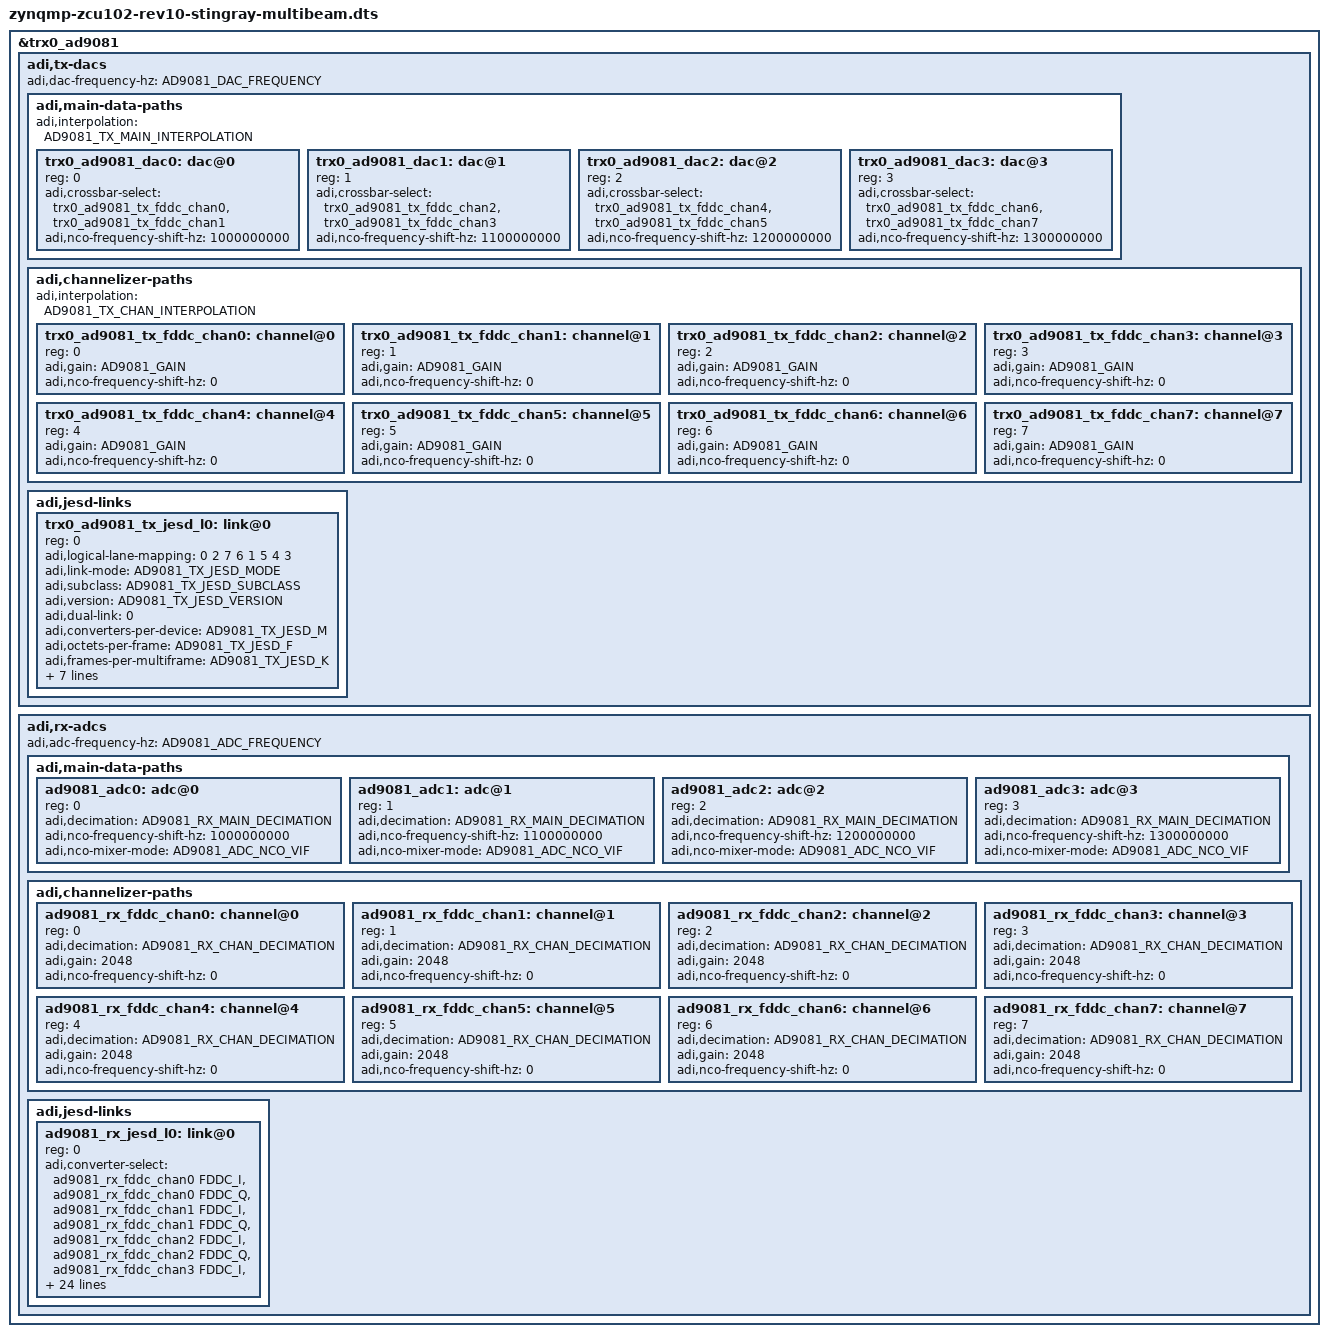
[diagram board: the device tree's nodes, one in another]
// SPDX-License-Identifier: GPL-2.0
/*
 * Analog Devices Stingray
 * https://wiki.analog.com/resources/eval/user-guides/quadmxfe/quick-start
 * https://wiki.analog.com/resources/tools-software/linux-drivers/iio-mxfe/ad9081
 *
 * hdl_project: <ad9081_fmca_ebz_x_band/zcu102>
 * board_revision: <>
 *
 * Copyright (C) 2019-2020 Analog Devices Inc.
 */

#include "zynqmp-zcu102-rev10-stingray.dts"

/*
 *	Lane Rate = 10 Gpbs
 *	Link Clock = 250 MHz
 */

#define AD9081_GAIN			2048

 /* TX path */
#define AD9081_DAC_FREQUENCY			12000000000
#define AD9081_TX_MAIN_INTERPOLATION		8
#define AD9081_TX_CHAN_INTERPOLATION		6

#define AD9081_TX_JESD_MODE			16
#define AD9081_TX_JESD_SUBCLASS			1
#define AD9081_TX_JESD_VERSION			1
#define AD9081_TX_JESD_L			8
#define AD9081_TX_JESD_M			16
#define AD9081_TX_JESD_F			4
#define AD9081_TX_JESD_S			1
#define AD9081_TX_JESD_K			32
#define AD9081_TX_JESD_N			16
#define AD9081_TX_JESD_NP			16
#define AD9081_TX_JESD_CS			0
#define AD9081_TX_JESD_HD			1


 /* RX path */
#define AD9081_ADC_FREQUENCY			6000000000
#define AD9081_RX_MAIN_DECIMATION		6
#define AD9081_RX_CHAN_DECIMATION		4

#define AD9081_RX_JESD_MODE			17
#define AD9081_RX_JESD_SUBCLASS			1
#define AD9081_RX_JESD_VERSION			1
#define AD9081_RX_JESD_L			8
#define AD9081_RX_JESD_M			16
#define AD9081_RX_JESD_F			4
#define AD9081_RX_JESD_S			1
#define AD9081_RX_JESD_K			32
#define AD9081_RX_JESD_N			16
#define AD9081_RX_JESD_NP			16
#define AD9081_RX_JESD_CS			0
#define AD9081_RX_JESD_HD			0


//#define AD9081_JRX_TPL_PHASE_ADJUST		15


&trx0_ad9081 {
	adi,tx-dacs {
		#size-cells = <0>;
		#address-cells = <1>;
		adi,dac-frequency-hz = /bits/ 64 <AD9081_DAC_FREQUENCY>;
		adi,main-data-paths {
			#address-cells = <1>;
			#size-cells = <0>;
			adi,interpolation = <AD9081_TX_MAIN_INTERPOLATION>;
			trx0_ad9081_dac0: dac@0 {
				reg = <0>;
				adi,crossbar-select = <&trx0_ad9081_tx_fddc_chan0>, <&trx0_ad9081_tx_fddc_chan1>;
				adi,nco-frequency-shift-hz = /bits/ 64 <1000000000>; /* 1100 MHz */
			};
			trx0_ad9081_dac1: dac@1 {
				reg = <1>;
				adi,crossbar-select = <&trx0_ad9081_tx_fddc_chan2>, <&trx0_ad9081_tx_fddc_chan3>;
				adi,nco-frequency-shift-hz = /bits/ 64 <1100000000>; /* 1100 MHz */
			};
			trx0_ad9081_dac2: dac@2 {
				reg = <2>;
				adi,crossbar-select = <&trx0_ad9081_tx_fddc_chan4>, <&trx0_ad9081_tx_fddc_chan5>; /* All 4 channels @ dac2 */
				adi,nco-frequency-shift-hz = /bits/ 64 <1200000000>;  /* 1200 MHz */
			};
			trx0_ad9081_dac3: dac@3 {
				reg = <3>;
				adi,crossbar-select = <&trx0_ad9081_tx_fddc_chan6>, <&trx0_ad9081_tx_fddc_chan7>; /* All 4 channels @ dac2 */
				adi,nco-frequency-shift-hz = /bits/ 64 <1300000000>; /* 1300 MHz */
			};
		};
		adi,channelizer-paths {
			#address-cells = <1>;
			#size-cells = <0>;
			adi,interpolation = <AD9081_TX_CHAN_INTERPOLATION>;
			trx0_ad9081_tx_fddc_chan0: channel@0 {
				reg = <0>;
				adi,gain = <AD9081_GAIN>; /* value * 10^(gain_dB/20) */
				adi,nco-frequency-shift-hz =  /bits/ 64 <0>;
			};
			trx0_ad9081_tx_fddc_chan1: channel@1 {
				reg = <1>;
				adi,gain = <AD9081_GAIN>; /* value * 10^(gain_dB/20) */
				adi,nco-frequency-shift-hz =  /bits/ 64 <0>;
			};
			trx0_ad9081_tx_fddc_chan2: channel@2 {
				reg = <2>;
				adi,gain = <AD9081_GAIN>; /* value * 10^(gain_dB/20) */
				adi,nco-frequency-shift-hz =  /bits/ 64 <0>;
			};
			trx0_ad9081_tx_fddc_chan3: channel@3 {
				reg = <3>;
				adi,gain = <AD9081_GAIN>; /* value * 10^(gain_dB/20) */
				adi,nco-frequency-shift-hz =  /bits/ 64 <0>;
			};
			trx0_ad9081_tx_fddc_chan4: channel@4 {
			    reg = <4>;
			    adi,gain = <AD9081_GAIN>; /* value * 10^(gain_dB/20) */
			    adi,nco-frequency-shift-hz =  /bits/ 64 <0>;
			};
			trx0_ad9081_tx_fddc_chan5: channel@5 {
			    reg = <5>;
			    adi,gain = <AD9081_GAIN>; /* value * 10^(gain_dB/20) */
			    adi,nco-frequency-shift-hz =  /bits/ 64 <0>;
			};
			trx0_ad9081_tx_fddc_chan6: channel@6 {
			    reg = <6>;
			    adi,gain = <AD9081_GAIN>; /* value * 10^(gain_dB/20) */
			    adi,nco-frequency-shift-hz =  /bits/ 64 <0>;
			};
			trx0_ad9081_tx_fddc_chan7: channel@7 {
			    reg = <7>;
			    adi,gain = <AD9081_GAIN>; /* value * 10^(gain_dB/20) */
			    adi,nco-frequency-shift-hz =  /bits/ 64 <0>;
			};
		};
		adi,jesd-links {
			#size-cells = <0>;
			#address-cells = <1>;
			trx0_ad9081_tx_jesd_l0: link@0 {
				#address-cells = <1>;
				#size-cells = <0>;
				reg = <0>;
				//adi,tpl-phase-adjust = <AD9081_JRX_TPL_PHASE_ADJUST>;
				adi,logical-lane-mapping = /bits/ 8 <0 2 7 6 1 5 4 3>;
				adi,link-mode = <AD9081_TX_JESD_MODE>;			/* JESD Quick Configuration Mode */
				adi,subclass = <AD9081_TX_JESD_SUBCLASS>;			/* JESD SUBCLASS 0,1,2 */
				adi,version = <AD9081_TX_JESD_VERSION>;			/* JESD VERSION 0=204A,1=204B,2=204C */
				adi,dual-link = <0>;			/* JESD Dual Link Mode */
				adi,converters-per-device = <AD9081_TX_JESD_M>;	/* JESD M */
				adi,octets-per-frame = <AD9081_TX_JESD_F>;		/* JESD F */
				adi,frames-per-multiframe = <AD9081_TX_JESD_K>;	/* JESD K */
				adi,converter-resolution = <AD9081_TX_JESD_N>;	/* JESD N */
				adi,bits-per-sample = <AD9081_TX_JESD_NP>;		/* JESD NP' */
				adi,control-bits-per-sample = <AD9081_TX_JESD_CS>;	/* JESD CS */
				adi,lanes-per-device = <AD9081_TX_JESD_L>;		/* JESD L */
				adi,samples-per-converter-per-frame = <AD9081_TX_JESD_S>; /* JESD S */
				adi,high-density = <AD9081_TX_JESD_HD>;			/* JESD HD */
			};
		};
	};
	adi,rx-adcs {
		#size-cells = <0>;
		#address-cells = <1>;
		adi,adc-frequency-hz = /bits/ 64 <AD9081_ADC_FREQUENCY>;
		adi,main-data-paths {
			#address-cells = <1>;
			#size-cells = <0>;
			ad9081_adc0: adc@0 {
				reg = <0>;
				adi,decimation = <AD9081_RX_MAIN_DECIMATION>;
				adi,nco-frequency-shift-hz =  /bits/ 64 <1000000000>;
				adi,nco-mixer-mode = <AD9081_ADC_NCO_VIF>;
			};
			ad9081_adc1: adc@1 {
				reg = <1>;
				adi,decimation = <AD9081_RX_MAIN_DECIMATION>;
				adi,nco-frequency-shift-hz =  /bits/ 64 <1100000000>;
				adi,nco-mixer-mode = <AD9081_ADC_NCO_VIF>;
			};
			ad9081_adc2: adc@2 {
				reg = <2>;
				adi,decimation = <AD9081_RX_MAIN_DECIMATION>;
				adi,nco-frequency-shift-hz =  /bits/ 64 <1200000000>;
				adi,nco-mixer-mode = <AD9081_ADC_NCO_VIF>;
			};
			ad9081_adc3: adc@3 {
				reg = <3>;
				adi,decimation = <AD9081_RX_MAIN_DECIMATION>;
				adi,nco-frequency-shift-hz =  /bits/ 64 <1300000000>;
				adi,nco-mixer-mode = <AD9081_ADC_NCO_VIF>;
			};
		};
		adi,channelizer-paths {
			#address-cells = <1>;
			#size-cells = <0>;
			ad9081_rx_fddc_chan0: channel@0 {
				reg = <0>;
				adi,decimation = <AD9081_RX_CHAN_DECIMATION>;
				adi,gain = <2048>; /* 2048 * 10^(gain_dB/20) */
				adi,nco-frequency-shift-hz =  /bits/ 64 <0>;
			};
			ad9081_rx_fddc_chan1: channel@1 {
				reg = <1>;
				adi,decimation = <AD9081_RX_CHAN_DECIMATION>;
				adi,gain = <2048>; /* 2048 * 10^(gain_dB/20) */
				adi,nco-frequency-shift-hz =  /bits/ 64 <0>;
			};
			ad9081_rx_fddc_chan2: channel@2 {
				reg = <2>;
				adi,decimation = <AD9081_RX_CHAN_DECIMATION>;
				adi,gain = <2048>; /* 2048 * 10^(gain_dB/20) */
				adi,nco-frequency-shift-hz =  /bits/ 64 <0>;
			};
			ad9081_rx_fddc_chan3: channel@3 {
				reg = <3>;
				adi,decimation = <AD9081_RX_CHAN_DECIMATION>;
				adi,gain = <2048>; /* 2048 * 10^(gain_dB/20) */
				adi,nco-frequency-shift-hz =  /bits/ 64 <0>;
			};
			ad9081_rx_fddc_chan4: channel@4 {
				reg = <4>;
				adi,decimation = <AD9081_RX_CHAN_DECIMATION>;
				adi,gain = <2048>; /* 2048 * 10^(gain_dB/20) */
				adi,nco-frequency-shift-hz =  /bits/ 64 <0>;
			};
			ad9081_rx_fddc_chan5: channel@5 {
				reg = <5>;
				adi,decimation = <AD9081_RX_CHAN_DECIMATION>;
				adi,gain = <2048>; /* 2048 * 10^(gain_dB/20) */
				adi,nco-frequency-shift-hz =  /bits/ 64 <0>;
			};
			ad9081_rx_fddc_chan6: channel@6 {
				reg = <6>;
				adi,decimation = <AD9081_RX_CHAN_DECIMATION>;
				adi,gain = <2048>; /* 2048 * 10^(gain_dB/20) */
				adi,nco-frequency-shift-hz =  /bits/ 64 <0>;
			};
			ad9081_rx_fddc_chan7: channel@7 {
				reg = <7>;
				adi,decimation = <AD9081_RX_CHAN_DECIMATION>;
				adi,gain = <2048>; /* 2048 * 10^(gain_dB/20) */
				adi,nco-frequency-shift-hz =  /bits/ 64 <0>;
			};
		};
		adi,jesd-links {
			#size-cells = <0>;
			#address-cells = <1>;
			ad9081_rx_jesd_l0: link@0 {
				reg = <0>;
				adi,converter-select =
					<&ad9081_rx_fddc_chan0 FDDC_I>, <&ad9081_rx_fddc_chan0 FDDC_Q>,
					<&ad9081_rx_fddc_chan1 FDDC_I>, <&ad9081_rx_fddc_chan1 FDDC_Q>,
					<&ad9081_rx_fddc_chan2 FDDC_I>, <&ad9081_rx_fddc_chan2 FDDC_Q>,
					<&ad9081_rx_fddc_chan3 FDDC_I>, <&ad9081_rx_fddc_chan3 FDDC_Q>,
					<&ad9081_rx_fddc_chan4 FDDC_I>, <&ad9081_rx_fddc_chan4 FDDC_Q>,
					<&ad9081_rx_fddc_chan5 FDDC_I>, <&ad9081_rx_fddc_chan5 FDDC_Q>,
					<&ad9081_rx_fddc_chan6 FDDC_I>, <&ad9081_rx_fddc_chan6 FDDC_Q>,
					<&ad9081_rx_fddc_chan7 FDDC_I>, <&ad9081_rx_fddc_chan7 FDDC_Q>;
				adi,logical-lane-mapping = /bits/ 8 <2 0 7 6 5 4 3 1>;
				adi,link-mode = <AD9081_RX_JESD_MODE>;			/* JESD Quick Configuration Mode */
				adi,subclass = <AD9081_RX_JESD_SUBCLASS>;			/* JESD SUBCLASS 0,1,2 */
				adi,version = <AD9081_RX_JESD_VERSION>;			/* JESD VERSION 0=204A,1=204B,2=204C */
				adi,dual-link = <0>;			/* JESD Dual Link Mode */
				adi,converters-per-device = <AD9081_RX_JESD_M>;	/* JESD M */
				adi,octets-per-frame = <AD9081_RX_JESD_F>;		/* JESD F */
				adi,frames-per-multiframe = <AD9081_RX_JESD_K>;	/* JESD K */
				adi,converter-resolution = <AD9081_RX_JESD_N>;	/* JESD N */
				adi,bits-per-sample = <AD9081_RX_JESD_NP>;		/* JESD NP' */
				adi,control-bits-per-sample = <AD9081_RX_JESD_CS>;	/* JESD CS */
				adi,lanes-per-device = <AD9081_RX_JESD_L>;		/* JESD L */
				adi,samples-per-converter-per-frame = <AD9081_RX_JESD_S>; /* JESD S */
				adi,high-density = <AD9081_RX_JESD_HD>;			/* JESD HD */
			};
		};
	};
};

